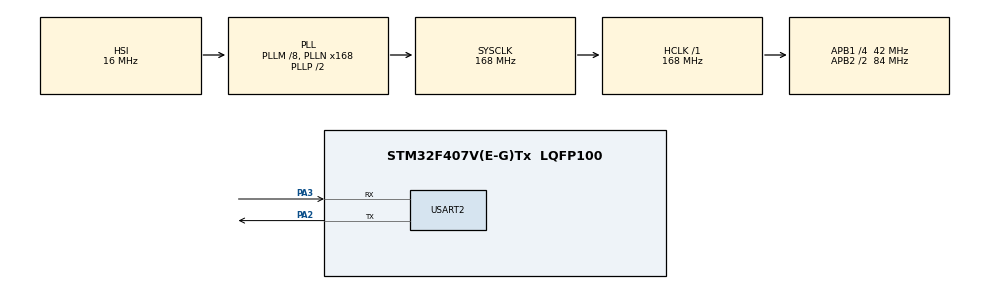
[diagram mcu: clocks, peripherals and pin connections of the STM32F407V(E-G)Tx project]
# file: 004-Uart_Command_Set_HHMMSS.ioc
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Mcu.Family=STM32F4
Mcu.Name=STM32F407V(E-G)Tx
Mcu.Package=LQFP100
NVIC.PriorityGroup=NVIC_PRIORITYGROUP_0
PA13.Mode=Serial_Wire
PA13.Signal=SYS_JTMS-SWDIO
PA14.Mode=Serial_Wire
PA14.Signal=SYS_JTCK-SWCLK
PA2.Mode=Asynchronous
PA2.Signal=USART2_TX
PA3.Mode=Asynchronous
PA3.Signal=USART2_RX
ProjectManager.HeapSize=0x200
ProjectManager.StackSize=0x400
ProjectManager.TargetToolchain=STM32CubeIDE
RCC.48MHZClocksFreq_Value=48000000
RCC.AHBFreq_Value=168000000
RCC.APB1CLKDivider=RCC_HCLK_DIV4
RCC.APB1Freq_Value=42000000
RCC.APB1TimFreq_Value=84000000
RCC.APB2CLKDivider=RCC_HCLK_DIV2
RCC.APB2Freq_Value=84000000
RCC.APB2TimFreq_Value=168000000
RCC.CortexFreq_Value=168000000
RCC.HCLKFreq_Value=168000000
RCC.HSE_VALUE=8000000
RCC.HSI_VALUE=16000000
RCC.PLLM=8
RCC.PLLN=168
RCC.PLLQ=7
RCC.SYSCLKFreq_VALUE=168000000
RCC.SYSCLKSource=RCC_SYSCLKSOURCE_PLLCLK
RCC.VCOOutputFreq_Value=336000000
USART2.VirtualMode=VM_ASYNC
VP_RTC_VS_RTC_Activate.Mode=RTC_Enabled
board=STM32F407G-DISC1

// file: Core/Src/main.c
/* USER CODE BEGIN Header */
/**
  ******************************************************************************
  * @file           : main.c
  * @brief          : Main program body
  ******************************************************************************
  * @attention
  *
  * Copyright (c) 2025 STMicroelectronics.
  * All rights reserved.
  *
  * This software is licensed under terms that can be found in the LICENSE file
  * in the root directory of this software component.
  * If no LICENSE file comes with this software, it is provided AS-IS.
  *
  ******************************************************************************
  */
/* USER CODE END Header */
#include "main.h"

/* USER CODE BEGIN Includes */
#include <string.h>
#include <stdio.h>
#include <stdlib.h>
/* USER CODE END Includes */

RTC_HandleTypeDef hrtc;

UART_HandleTypeDef huart2;

/* USER CODE BEGIN PV */
char rxBuffer[32]; // buffer for UART reception

// Redirect printf to UART
int __io_putchar(int ch) {
    HAL_UART_Transmit(&huart2, (uint8_t *)&ch, 1, HAL_MAX_DELAY);
    return ch;
}
/* USER CODE END PV */

void SystemClock_Config(void);
static void MX_GPIO_Init(void);
static void MX_USART2_UART_Init(void);
static void MX_RTC_Init(void);

int main(void)
{

  /* MCU Configuration--------------------------------------------------------*/

  /* Reset of all peripherals, Initializes the Flash interface and the Systick. */
  HAL_Init();

  /* Configure the system clock */
  SystemClock_Config();

  /* Initialize all configured peripherals */
  MX_GPIO_Init();
  MX_USART2_UART_Init();
  MX_RTC_Init();
  /* USER CODE BEGIN 2 */

  RTC_TimeTypeDef sTime;
  RTC_DateTypeDef sDate;

  printf("RTC UART Command Example\r\n");
  printf("Use: SET TIME HH:MM:SS\r\n");

  /* USER CODE END 2 */

  /* Infinite loop */
  /* USER CODE BEGIN WHILE */
  while (1)
  {

      memset(rxBuffer, 0, sizeof(rxBuffer));
       HAL_UART_Receive(&huart2, (uint8_t *)rxBuffer, sizeof(rxBuffer)-1, 5000); // wait 5s

       if (strncmp(rxBuffer, "SET TIME", 8) == 0) {
           int hh, mm, ss;
           if (sscanf(rxBuffer, "SET TIME %d:%d:%d", &hh, &mm, &ss) == 3) {
               if (hh < 24 && mm < 60 && ss < 60) {
                   RTC_TimeTypeDef newTime = {0};
                   newTime.Hours = hh;
                   newTime.Minutes = mm;
                   newTime.Seconds = ss;
                   newTime.TimeFormat = RTC_HOURFORMAT12_AM;
                   HAL_RTC_SetTime(&hrtc, &newTime, RTC_FORMAT_BIN);
                   printf("Time updated to %02d:%02d:%02d\r\n", hh, mm, ss);
               } else {
                   printf("Invalid time format!\r\n");
               }
           } else {
               printf("Invalid command syntax!\r\n");
           }
       }

       // Print current time
       HAL_RTC_GetTime(&hrtc, &sTime, RTC_FORMAT_BIN);
       HAL_RTC_GetDate(&hrtc, &sDate, RTC_FORMAT_BIN);
       printf("Current Time: %02d:%02d:%02d\r\n", sTime.Hours, sTime.Minutes, sTime.Seconds);
       HAL_Delay(1000);
    /* USER CODE END WHILE */

  }
}

void SystemClock_Config(void)
{
  RCC_OscInitTypeDef RCC_OscInitStruct = {0};
  RCC_ClkInitTypeDef RCC_ClkInitStruct = {0};

  /** Configure the main internal regulator output voltage
  */
  __HAL_RCC_PWR_CLK_ENABLE();
  __HAL_PWR_VOLTAGESCALING_CONFIG(PWR_REGULATOR_VOLTAGE_SCALE1);

  /** Initializes the RCC Oscillators according to the specified parameters
  * in the RCC_OscInitTypeDef structure.
  */
  RCC_OscInitStruct.OscillatorType = RCC_OSCILLATORTYPE_HSI|RCC_OSCILLATORTYPE_LSI;
  RCC_OscInitStruct.HSIState = RCC_HSI_ON;
  RCC_OscInitStruct.HSICalibrationValue = RCC_HSICALIBRATION_DEFAULT;
  RCC_OscInitStruct.LSIState = RCC_LSI_ON;
  RCC_OscInitStruct.PLL.PLLState = RCC_PLL_ON;
  RCC_OscInitStruct.PLL.PLLSource = RCC_PLLSOURCE_HSI;
  RCC_OscInitStruct.PLL.PLLM = 8;
  RCC_OscInitStruct.PLL.PLLN = 168;
  RCC_OscInitStruct.PLL.PLLP = RCC_PLLP_DIV2;
  RCC_OscInitStruct.PLL.PLLQ = 7;
  if (HAL_RCC_OscConfig(&RCC_OscInitStruct) != HAL_OK)
  {
    Error_Handler();
  }

  /** Initializes the CPU, AHB and APB buses clocks
  */
  RCC_ClkInitStruct.ClockType = RCC_CLOCKTYPE_HCLK|RCC_CLOCKTYPE_SYSCLK
                              |RCC_CLOCKTYPE_PCLK1|RCC_CLOCKTYPE_PCLK2;
  RCC_ClkInitStruct.SYSCLKSource = RCC_SYSCLKSOURCE_PLLCLK;
  RCC_ClkInitStruct.AHBCLKDivider = RCC_SYSCLK_DIV1;
  RCC_ClkInitStruct.APB1CLKDivider = RCC_HCLK_DIV4;
  RCC_ClkInitStruct.APB2CLKDivider = RCC_HCLK_DIV2;

  if (HAL_RCC_ClockConfig(&RCC_ClkInitStruct, FLASH_LATENCY_5) != HAL_OK)
  {
    Error_Handler();
  }
}

static void MX_RTC_Init(void)
{

  /** Initialize RTC Only
  */
  hrtc.Instance = RTC;
  hrtc.Init.HourFormat = RTC_HOURFORMAT_24;
  hrtc.Init.AsynchPrediv = 127;
  hrtc.Init.SynchPrediv = 255;
  hrtc.Init.OutPut = RTC_OUTPUT_DISABLE;
  hrtc.Init.OutPutPolarity = RTC_OUTPUT_POLARITY_HIGH;
  hrtc.Init.OutPutType = RTC_OUTPUT_TYPE_OPENDRAIN;
  if (HAL_RTC_Init(&hrtc) != HAL_OK)
  {
    Error_Handler();
  }

}

static void MX_USART2_UART_Init(void)
{

  huart2.Instance = USART2;
  huart2.Init.BaudRate = 115200;
  huart2.Init.WordLength = UART_WORDLENGTH_8B;
  huart2.Init.StopBits = UART_STOPBITS_1;
  huart2.Init.Parity = UART_PARITY_NONE;
  huart2.Init.Mode = UART_MODE_TX_RX;
  huart2.Init.HwFlowCtl = UART_HWCONTROL_NONE;
  huart2.Init.OverSampling = UART_OVERSAMPLING_16;
  if (HAL_UART_Init(&huart2) != HAL_OK)
  {
    Error_Handler();
  }

}

static void MX_GPIO_Init(void)
{

  /* GPIO Ports Clock Enable */
  __HAL_RCC_GPIOA_CLK_ENABLE();

}

void Error_Handler(void)
{
  __disable_irq();
  while (1)
  {
  }
}
